# STM32H753xx register map
File version: 1.0
Registers are 32-bit, access not given, reset 0x0 unless marked. A register's access mark holds for its fields unless they carry their own. Offsets are from the block's base; [hi:lo] are bit positions; {n}, {i} and the like mark numbered series.

## HASH
Base 0x48021400
0x00 CR
  [16] LKEY, [13] MDMAT, [12] DINNE, [11:8] NBW, [18:7] ALGO, [6] MODE, [5:4] DATATYPE, [3] DMAE, [2] INIT
0x04 DIN
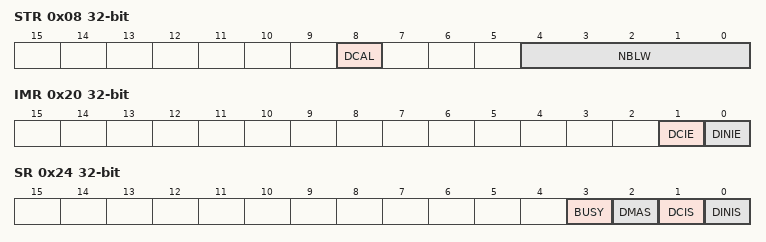
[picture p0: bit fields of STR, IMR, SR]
0x08 STR
  [8] DCAL, [4:0] NBLW
0x0C HR.0
0x10 HR.1
0x14 HR.2
0x18 HR.3
0x1C HR.4
0x20 IMR
  [1] DCIE, [0] DINIE
0x24 SR
  [3] BUSY, [2] DMAS, [1] DCIS, [0] DINIS
0xF8 CSR.0
0xFC CSR.1
0x100 CSR.2
0x104 CSR.3
0x108 CSR.4
0x10C CSR.5
0x110 CSR.6
0x114 CSR.7
0x118 CSR.8
0x11C CSR.9
0x120 CSR.10
0x124 CSR.11
0x128 CSR.12
0x12C CSR.13
0x130 CSR.14
0x134 CSR.15
0x138 CSR.16
0x13C CSR.17
0x140 CSR.18
0x144 CSR.19
0x148 CSR.20
0x14C CSR.21
0x150 CSR.22
0x154 CSR.23
0x158 CSR.24
0x15C CSR.25
0x160 CSR.26
0x164 CSR.27
0x168 CSR.28
0x16C CSR.29
0x170 CSR.30
0x174 CSR.31
0x178 CSR.32
0x17C CSR.33
0x180 CSR.34
0x184 CSR.35
0x188 CSR.36
0x18C CSR.37
0x190 CSR.38
0x194 CSR.39
0x198 CSR.40
0x19C CSR.41
0x1A0 CSR.42
0x1A4 CSR.43
0x1A8 CSR.44
0x1AC CSR.45
0x1B0 CSR.46
0x1B4 CSR.47
0x1B8 CSR.48
0x1BC CSR.49
0x1C0 CSR.50
0x1C4 CSR.51
0x1C8 CSR.52
0x1CC CSR.53

## HASH_DIGEST
Base 0x48021710
0x00 HR.0
0x04 HR.1
0x08 HR.2
0x0C HR.3
0x10 HR.4
0x14 HR.5
0x18 HR.6
0x1C HR.7

## RNG
Base 0x48021800
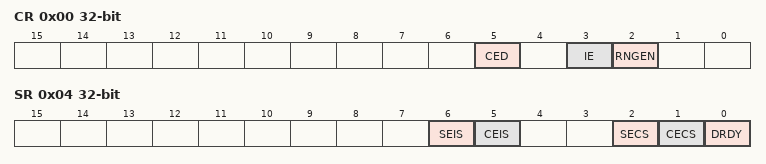
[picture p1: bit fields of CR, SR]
0x00 CR
  [5] CED, [3] IE, [2] RNGEN
0x04 SR
  [6] SEIS, [5] CEIS, [2] SECS, [1] CECS, [0] DRDY
0x08 DR

## SDMMC2
Base 0x48022400
Same registers: SDMMC1 0x52007000
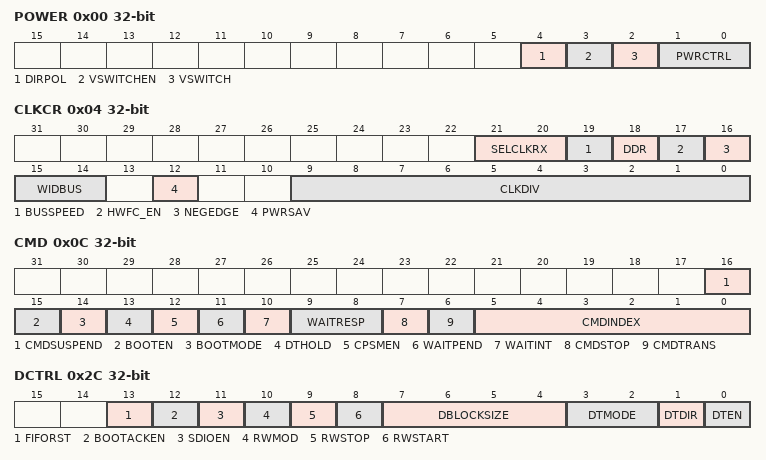
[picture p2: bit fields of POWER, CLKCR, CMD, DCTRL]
0x00 POWER
  [4] DIRPOL, [3] VSWITCHEN, [2] VSWITCH, [1:0] PWRCTRL
0x04 CLKCR
  [21:20] SELCLKRX, [19] BUSSPEED, [18] DDR, [17] HWFC_EN, [16] NEGEDGE, [15:14] WIDBUS, [12] PWRSAV, [9:0] CLKDIV
0x08 ARG
  [31:0] CMDARG
0x0C CMD
  [16] CMDSUSPEND, [15] BOOTEN, [14] BOOTMODE, [13] DTHOLD, [12] CPSMEN, [11] WAITPEND, [10] WAITINT, [9:8] WAITRESP, [7] CMDSTOP, [6] CMDTRANS, [5:0] CMDINDEX
0x10 RESPCMD
  [5:0] RESPCMD
{0x10+4i} RESP{i} (i=1..4)
  [31:0] CARDSTATUS{i}
0x24 DTIMER
  [31:0] DATATIME
0x28 DLEN
  [24:0] DATALENGTH
0x2C DCTRL
  [13] FIFORST, [12] BOOTACKEN, [11] SDIOEN, [10] RWMOD, [9] RWSTOP, [8] RWSTART, [7:4] DBLOCKSIZE, [3:2] DTMODE, [1] DTDIR, [0] DTEN
0x30 DCOUNT
  [24:0] DATACOUNT
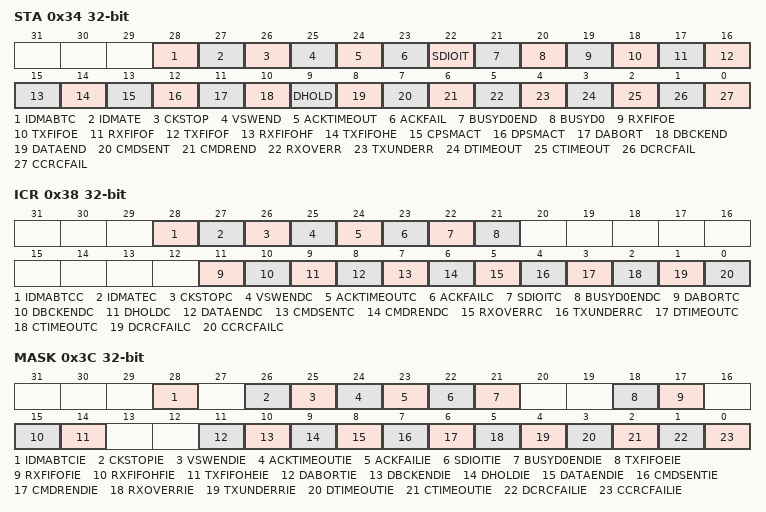
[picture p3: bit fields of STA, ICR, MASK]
0x34 STA
  [28] IDMABTC, [27] IDMATE, [26] CKSTOP, [25] VSWEND, [24] ACKTIMEOUT, [23] ACKFAIL, [22] SDIOIT, [21] BUSYD0END, [20] BUSYD0, [19] RXFIFOE, [18] TXFIFOE, [17] RXFIFOF, [16] TXFIFOF, [15] RXFIFOHF, [14] TXFIFOHE, [13] CPSMACT, [12] DPSMACT, [11] DABORT, [10] DBCKEND, [9] DHOLD, [8] DATAEND, [7] CMDSENT, [6] CMDREND, [5] RXOVERR, [4] TXUNDERR, [3] DTIMEOUT, [2] CTIMEOUT, [1] DCRCFAIL, [0] CCRCFAIL
0x38 ICR
  [28] IDMABTCC, [27] IDMATEC, [26] CKSTOPC, [25] VSWENDC, [24] ACKTIMEOUTC, [23] ACKFAILC, [22] SDIOITC, [21] BUSYD0ENDC, [11] DABORTC, [10] DBCKENDC, [9] DHOLDC, [8] DATAENDC, [7] CMDSENTC, [6] CMDRENDC, [5] RXOVERRC, [4] TXUNDERRC, [3] DTIMEOUTC, [2] CTIMEOUTC, [1] DCRCFAILC, [0] CCRCFAILC
0x3C MASK
  [28] IDMABTCIE, [26] CKSTOPIE, [25] VSWENDIE, [24] ACKTIMEOUTIE, [23] ACKFAILIE, [22] SDIOITIE, [21] BUSYD0ENDIE, [18] TXFIFOEIE, [17] RXFIFOFIE, [15] RXFIFOHFIE, [14] TXFIFOHEIE, [11] DABORTIE, [10] DBCKENDIE, [9] DHOLDIE, [8] DATAENDIE, [7] CMDSENTIE, [6] CMDRENDIE, [5] RXOVERRIE, [4] TXUNDERRIE, [3] DTIMEOUTIE, [2] CTIMEOUTIE, [1] DCRCFAILIE, [0] CCRCFAILIE
0x40 ACKTIME
  [24:0] ACKTIME
0x50 IDMACTRL
0x54 IDMABSIZE
  [12:5] IDMABNDT
0x58 IDMABASE0
0x5C IDMABASE1
0x80 FIFO
  [31:0] FIFODATA
0x3FC IPVR

## DLYB_SDMMC2
Base 0x48022800
Same registers: DLYB_QUADSPI 0x52006000, DLYB_SDMMC1 0x52008000
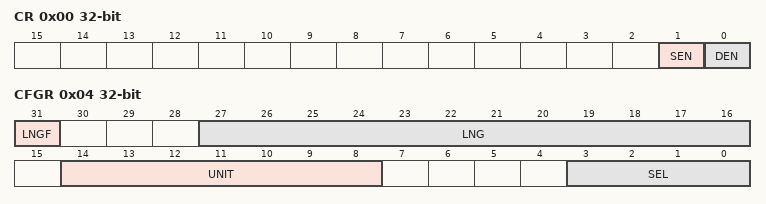
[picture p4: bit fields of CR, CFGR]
0x00 CR
  [1] SEN, [0] DEN
0x04 CFGR
  [31] LNGF, [27:16] LNG, [14:8] UNIT, [3:0] SEL

## RAMECC2
Base 0x48023000
Same registers: RAMECC1 0x52009000, RAMECC3 0x58027000
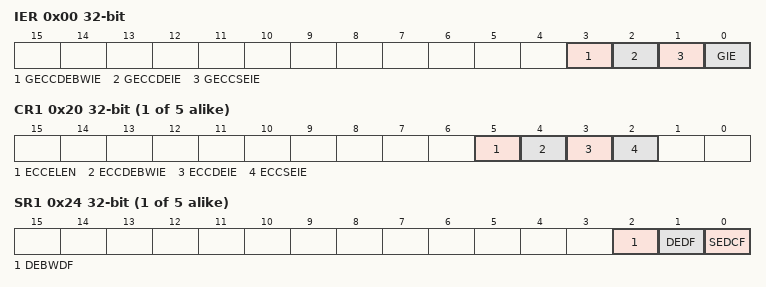
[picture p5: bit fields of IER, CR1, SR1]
0x00 IER
  [3] GECCDEBWIE, [2] GECCDEIE, [1] GECCSEIE, [0] GIE
{0x0+0x20*i} CR{i} (i=1..5)
  [5] ECCELEN, [4] ECCDEBWIE, [3] ECCDEIE, [2] ECCSEIE
{0x4+0x20*i} SR{i} (i=1..5)
  [2] DEBWDF, [1] DEDF, [0] SEDCF
{0xC+0x20*i} FAR{i} (i=1..5)
  [31:0] FDATAL
{0x18+0x20*i} FDRL{i} (i=1..5)
{0x28+0x20*i} FDRH{i} (i=1..5)
{0x3C+0x20*i} FECR{i} (i=1..5)
  [31:0] FEC
